# ATmega3290PA device description
Architecture: AVR8; Family: megaAVR
Registers are 8-bit, access not given, no defined reset value unless marked. A register's access mark holds for its fields unless they carry their own. Offsets are from the block's base; [hi:lo] are bit positions.

## WDT — Watchdog Timer
Instances: WDT 0x00
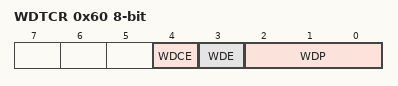
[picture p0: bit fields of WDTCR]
0x60 WDTCR — Watchdog Timer Control Register
  [4] WDCE — Watchdog Change Enable
  [3] WDE — Watch Dog Enable
  [2:0] WDP — Watch Dog Timer Prescaler bits
    0=Oscillator Cycles 16K; 1=Oscillator Cycles 32K; 2=Oscillator Cycles 64K; 3=Oscillator Cycles 128K; 4=Oscillator Cycles 256K; 5=Oscillator Cycles 512K; 6=Oscillator Cycles 1024K; 7=Oscillator Cycles 2048K

## EEPROM
Instances: EEPROM 0x00
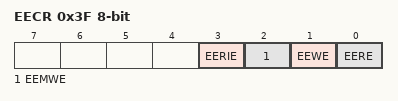
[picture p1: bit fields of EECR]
0x3F EECR — EEPROM Control Register
  [3] EERIE — EEPROM Ready Interrupt Enable
  [2] EEMWE — EEPROM Master Write Enable
  [1] EEWE — EEPROM Write Enable
  [0] EERE — EEPROM Read Enable
0x40 EEDR — EEPROM Data Register
0x41 EEAR 16-bit bits used 9:0 — EEPROM Read/Write Access Bytes

## SPI — Serial Peripheral Interface
Instances: SPI 0x00
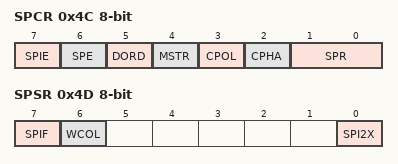
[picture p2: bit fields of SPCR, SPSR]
0x4C SPCR — SPI Control Register
  [7] SPIE — SPI Interrupt Enable
  [6] SPE — SPI Enable
  [5] DORD — Data Order
  [4] MSTR — Master/Slave Select
  [3] CPOL — Clock polarity
  [2] CPHA — Clock Phase
  [1:0] SPR — SPI Clock Rate Selects
    0=fosc/4; 1=fosc/16; 2=fosc/64; 3=fosc/128; 4=fosc/2; 5=fosc/8; 6=fosc/32; 7=fosc/64
0x4D SPSR — SPI Status Register
  [7] SPIF — SPI Interrupt Flag
  [6] WCOL — Write Collision Flag
  [0] SPI2X — Double SPI Speed Bit
0x4E SPDR — SPI Data Register

## PORTA — I/O Port
Instances: PORTA 0x00
0x20 PINA — Port A Input Pins
0x21 DDRA — Port A Data Direction Register
0x22 PORTA — Port A Data Register

## PORTB — I/O Port
Instances: PORTB 0x00
0x23 PINB — Port B Input Pins
0x24 DDRB — Port B Data Direction Register
0x25 PORTB — Port B Data Register

## PORTC — I/O Port
Instances: PORTC 0x00
0x26 PINC — Port C Input Pins
0x27 DDRC — Port C Data Direction Register
0x28 PORTC — Port C Data Register

## PORTD — I/O Port
Instances: PORTD 0x00
0x29 PIND — Port D Input Pins
0x2A DDRD — Port D Data Direction Register
0x2B PORTD — Port D Data Register

## PORTE — I/O Port
Instances: PORTE 0x00
0x2C PINE — Input Pins, Port E
0x2D DDRE — Data Direction Register, Port E
0x2E PORTE — Data Register, Port E

## PORTF — I/O Port
Instances: PORTF 0x00
0x2F PINF — Input Pins, Port F
0x30 DDRF — Data Direction Register, Port F
0x31 PORTF — Data Register, Port F

## PORTG — I/O Port
Instances: PORTG 0x00
0x32 PING bits used 5:0 — Port G Input Pins
0x33 DDRG bits used 4:0 — Port G Data Direction Register
0x34 PORTG bits used 4:0 — Port G Data Register

## PORTH — I/O Port
Instances: PORTH 0x00
0xD8 PINH — PORT H Input Pins
0xD9 DDRH — PORT H Data Direction Register
0xDA PORTH — PORT H Data Register

## PORTJ — I/O Port
Instances: PORTJ 0x00
0xDB PINJ bits used 6:0 — PORT J Input Pins
0xDC DDRJ bits used 6:0 — PORT J Data Direction Register
0xDD PORTJ bits used 6:0 — PORT J Data Register

## AC — Analog Comparator
Instances: AC 0x00
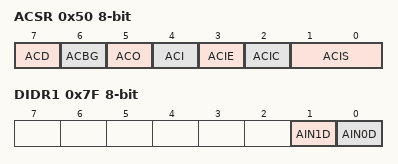
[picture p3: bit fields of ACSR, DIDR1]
0x50 ACSR — Analog Comparator Control And Status Register
  [7] ACD — Analog Comparator Disable
  [6] ACBG — Analog Comparator Bandgap Select
  [5] ACO — Analog Compare Output
  [4] ACI — Analog Comparator Interrupt Flag
  [3] ACIE — Analog Comparator Interrupt Enable
  [2] ACIC — Analog Comparator Input Capture Enable
  [1:0] ACIS — Analog Comparator Interrupt Mode Select bits
    0=Interrupt on Toggle; 2=Interrupt on Falling Edge; 3=Interrupt on Rising Edge
0x7B ADCSRB — ADC Control and Status Register B
  [6] ACME — Analog Comparator Multiplexer Enable
0x7F DIDR1 — Digital Input Disable Register 1
  [1] AIN1D — AIN1 Digital Input Disable
  [0] AIN0D — AIN0 Digital Input Disable
